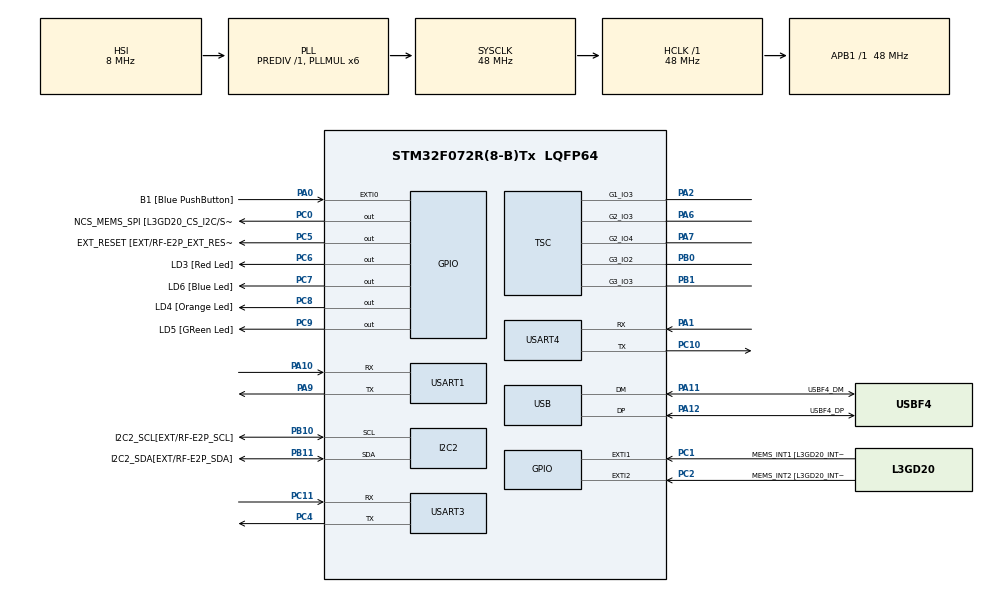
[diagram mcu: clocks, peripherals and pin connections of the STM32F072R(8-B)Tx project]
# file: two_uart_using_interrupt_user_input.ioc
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I2C2.Timing=0x20303E5D
Mcu.Family=STM32F0
Mcu.Name=STM32F072R(8-B)Tx
Mcu.Package=LQFP64
NVIC.USART1_IRQn=true\:0\:0\:false\:false\:true\:true\:true\:true
NVIC.USART3_4_IRQn=true\:0\:0\:false\:false\:true\:true\:true\:true
PA0.GPIO_Label=B1 [Blue PushButton]
PA0.GPIO_ModeDefaultEXTI=GPIO_MODE_EVT_RISING
PA0.Signal=GPXTI0
PA1.Mode=Asynchronous
PA1.Signal=USART4_RX
PA10.Mode=Asynchronous
PA10.Signal=USART1_RX
PA11.GPIO_Label=USBF4_DM
PA11.Mode=Device
PA11.Signal=USB_DM
PA12.GPIO_Label=USBF4_DP
PA12.Mode=Device
PA12.Signal=USB_DP
PA13.GPIO_Label=SWDIO
PA13.Mode=Serial_Wire
PA13.Signal=SYS_SWDIO
PA14.GPIO_Label=SWCLK
PA14.Mode=Serial_Wire
PA14.Signal=SYS_SWCLK
PA2.Mode=G1_IO3-Channel
PA2.Signal=TSC_G1_IO3
PA3.Signal=TSC_G1_IO4
PA6.Mode=G2_IO3-Channel
PA6.Signal=TSC_G2_IO3
PA7.Mode=G2_IO4-Sampling
PA7.Signal=TSC_G2_IO4
PA9.Mode=Asynchronous
PA9.Signal=USART1_TX
PB0.Mode=G3_IO2-Channel
PB0.Signal=TSC_G3_IO2
PB1.Mode=G3_IO3-Sampling
PB1.Signal=TSC_G3_IO3
PB10.GPIO_Label=I2C2_SCL[EXT/RF-E2P_SCL]
PB10.GPIO_Pu=GPIO_PULLUP
PB10.Mode=I2C
PB10.Signal=I2C2_SCL
PB11.GPIO_Label=I2C2_SDA[EXT/RF-E2P_SDA]
PB11.GPIO_Pu=GPIO_PULLUP
PB11.Mode=I2C
PB11.Signal=I2C2_SDA
PB13.Signal=USART3_CTS
PB14.GPIO_Label=SPI2_MISO [L3GD20_SDO]
PB14.Signal=SPI2_MISO
PB15.GPIO_Label=SPI2_MOSI [L3GD20_SDA/SDI]
PB15.Signal=SPI2_MOSI
PC0.GPIO_Label=NCS_MEMS_SPI [L3GD20_CS_I2C/SPI]
PC0.Signal=GPIO_Output
PC1.GPIO_Label=MEMS_INT1 [L3GD20_INT1]
PC1.GPIO_ModeDefaultEXTI=GPIO_MODE_EVT_RISING
PC1.Signal=GPXTI1
PC10.Mode=Asynchronous
PC10.Signal=USART4_TX
PC11.Mode=Asynchronous
PC11.Signal=USART3_RX
PC2.GPIO_Label=MEMS_INT2 [L3GD20_INT2]
PC2.GPIO_ModeDefaultEXTI=GPIO_MODE_EVT_RISING
PC2.Signal=GPXTI2
PC4.Mode=Asynchronous
PC4.Signal=USART3_TX
PC5.GPIO_Label=EXT_RESET [EXT/RF-E2P_EXT_RESET]
PC5.Signal=GPIO_Output
PC6.GPIO_Label=LD3 [Red Led]
PC6.Signal=GPIO_Output
PC7.GPIO_Label=LD6 [Blue Led]
PC7.Signal=GPIO_Output
PC8.GPIO_Label=LD4 [Orange Led]
PC8.Signal=GPIO_Output
PC9.GPIO_Label=LD5 [GReen Led]
PC9.Signal=GPIO_Output
ProjectManager.HeapSize=0x200
ProjectManager.StackSize=0x400
ProjectManager.TargetToolchain=STM32CubeIDE
RCC.AHBFreq_Value=48000000
RCC.APB1Freq_Value=48000000
RCC.APB1TimFreq_Value=48000000
RCC.HCLKFreq_Value=48000000
RCC.PLLMUL=RCC_PLL_MUL6
RCC.SYSCLKFreq_VALUE=48000000
RCC.SYSCLKSource=RCC_SYSCLKSOURCE_PLLCLK
TSC.ChannelIOs-G1_IO3-Channel=TSC_GROUP1_IO3
TSC.ChannelIOs-G2_IO3-Channel=TSC_GROUP2_IO3
TSC.ChannelIOs-G3_IO2-Channel=TSC_GROUP3_IO2
TSC.SamplingIOs-G2_IO4-Sampling=TSC_GROUP2_IO4
TSC.SamplingIOs-G3_IO3-Sampling=TSC_GROUP3_IO3
USART1.VirtualMode-Asynchronous=VM_ASYNC
USART3.VirtualMode-Asynchronous=VM_ASYNC
USART4.VirtualMode-Asynchronous=VM_ASYNC
USB.phy_itface=PCD_PHY_EMBEDDED
USB.speed=PCD_SPEED_FULL
board=STM32F072B-DISCO

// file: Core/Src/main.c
/* USER CODE BEGIN Header */
/**
  ******************************************************************************
  * @file           : main.c
  * @brief          : Main program body
  ******************************************************************************
  * @attention
  *
  * Copyright (c) 2026 STMicroelectronics.
  * All rights reserved.
  *
  * This software is licensed under terms that can be found in the LICENSE file
  * in the root directory of this software component.
  * If no LICENSE file comes with this software, it is provided AS-IS.
  *
  ******************************************************************************
  */
/* USER CODE END Header */
#include "main.h"

I2C_HandleTypeDef hi2c2;

TSC_HandleTypeDef htsc;

UART_HandleTypeDef huart1;
UART_HandleTypeDef huart3;
UART_HandleTypeDef huart4;

PCD_HandleTypeDef hpcd_USB_FS;

/* USER CODE BEGIN PV */
uint8_t usart3_rx;
uint8_t usart4_rx;

volatile uint8_t usart3_flag = 0;
volatile uint8_t usart4_flag = 0;
/* USER CODE END PV */

void SystemClock_Config(void);
static void MX_GPIO_Init(void);
static void MX_I2C2_Init(void);
static void MX_TSC_Init(void);
static void MX_USB_PCD_Init(void);
static void MX_USART1_UART_Init(void);
static void MX_USART4_UART_Init(void);
static void MX_USART3_UART_Init(void);

int main(void)
{

  /* MCU Configuration--------------------------------------------------------*/

  /* Reset of all peripherals, Initializes the Flash interface and the Systick. */
  HAL_Init();

  /* Configure the system clock */
  SystemClock_Config();

  /* Initialize all configured peripherals */
  MX_GPIO_Init();
  MX_I2C2_Init();
  MX_TSC_Init();
  MX_USB_PCD_Init();
  MX_USART1_UART_Init();
  MX_USART4_UART_Init();
  MX_USART3_UART_Init();
  /* USER CODE BEGIN 2 */
  HAL_UART_Receive_IT(&huart3, &usart3_rx, 1);
  HAL_UART_Receive_IT(&huart4, &usart4_rx, 1);
  /* USER CODE END 2 */

  /* Infinite loop */
  /* USER CODE BEGIN WHILE */
  while (1)
  {
      if (usart3_flag)
      {
          usart3_flag = 0;

          HAL_UART_Transmit(&huart4,
                            &usart3_rx,
                            1,
                            HAL_MAX_DELAY);
      }

      if (usart4_flag)
      {
          usart4_flag = 0;

          HAL_UART_Transmit(&huart3,
                            &usart4_rx,
                            1,
                            HAL_MAX_DELAY);
      }
  }
}

void SystemClock_Config(void)
{
  RCC_OscInitTypeDef RCC_OscInitStruct = {0};
  RCC_ClkInitTypeDef RCC_ClkInitStruct = {0};
  RCC_PeriphCLKInitTypeDef PeriphClkInit = {0};

  /** Initializes the RCC Oscillators according to the specified parameters
  * in the RCC_OscInitTypeDef structure.
  */
  RCC_OscInitStruct.OscillatorType = RCC_OSCILLATORTYPE_HSI|RCC_OSCILLATORTYPE_HSI48;
  RCC_OscInitStruct.HSIState = RCC_HSI_ON;
  RCC_OscInitStruct.HSI48State = RCC_HSI48_ON;
  RCC_OscInitStruct.HSICalibrationValue = RCC_HSICALIBRATION_DEFAULT;
  RCC_OscInitStruct.PLL.PLLState = RCC_PLL_ON;
  RCC_OscInitStruct.PLL.PLLSource = RCC_PLLSOURCE_HSI;
  RCC_OscInitStruct.PLL.PLLMUL = RCC_PLL_MUL6;
  RCC_OscInitStruct.PLL.PREDIV = RCC_PREDIV_DIV1;
  if (HAL_RCC_OscConfig(&RCC_OscInitStruct) != HAL_OK)
  {
    Error_Handler();
  }

  /** Initializes the CPU, AHB and APB buses clocks
  */
  RCC_ClkInitStruct.ClockType = RCC_CLOCKTYPE_HCLK|RCC_CLOCKTYPE_SYSCLK
                              |RCC_CLOCKTYPE_PCLK1;
  RCC_ClkInitStruct.SYSCLKSource = RCC_SYSCLKSOURCE_PLLCLK;
  RCC_ClkInitStruct.AHBCLKDivider = RCC_SYSCLK_DIV1;
  RCC_ClkInitStruct.APB1CLKDivider = RCC_HCLK_DIV1;

  if (HAL_RCC_ClockConfig(&RCC_ClkInitStruct, FLASH_LATENCY_1) != HAL_OK)
  {
    Error_Handler();
  }
  PeriphClkInit.PeriphClockSelection = RCC_PERIPHCLK_USB|RCC_PERIPHCLK_USART1;
  PeriphClkInit.Usart1ClockSelection = RCC_USART1CLKSOURCE_PCLK1;
  PeriphClkInit.UsbClockSelection = RCC_USBCLKSOURCE_HSI48;

  if (HAL_RCCEx_PeriphCLKConfig(&PeriphClkInit) != HAL_OK)
  {
    Error_Handler();
  }
}

static void MX_I2C2_Init(void)
{

  hi2c2.Instance = I2C2;
  hi2c2.Init.Timing = 0x20303E5D;
  hi2c2.Init.OwnAddress1 = 0;
  hi2c2.Init.AddressingMode = I2C_ADDRESSINGMODE_7BIT;
  hi2c2.Init.DualAddressMode = I2C_DUALADDRESS_DISABLE;
  hi2c2.Init.OwnAddress2 = 0;
  hi2c2.Init.OwnAddress2Masks = I2C_OA2_NOMASK;
  hi2c2.Init.GeneralCallMode = I2C_GENERALCALL_DISABLE;
  hi2c2.Init.NoStretchMode = I2C_NOSTRETCH_DISABLE;
  if (HAL_I2C_Init(&hi2c2) != HAL_OK)
  {
    Error_Handler();
  }

  /** Configure Analogue filter
  */
  if (HAL_I2CEx_ConfigAnalogFilter(&hi2c2, I2C_ANALOGFILTER_ENABLE) != HAL_OK)
  {
    Error_Handler();
  }

  /** Configure Digital filter
  */
  if (HAL_I2CEx_ConfigDigitalFilter(&hi2c2, 0) != HAL_OK)
  {
    Error_Handler();
  }

}

static void MX_TSC_Init(void)
{

  /** Configure the TSC peripheral
  */
  htsc.Instance = TSC;
  htsc.Init.CTPulseHighLength = TSC_CTPH_2CYCLES;
  htsc.Init.CTPulseLowLength = TSC_CTPL_2CYCLES;
  htsc.Init.SpreadSpectrum = DISABLE;
  htsc.Init.SpreadSpectrumDeviation = 1;
  htsc.Init.SpreadSpectrumPrescaler = TSC_SS_PRESC_DIV1;
  htsc.Init.PulseGeneratorPrescaler = TSC_PG_PRESC_DIV4;
  htsc.Init.MaxCountValue = TSC_MCV_8191;
  htsc.Init.IODefaultMode = TSC_IODEF_OUT_PP_LOW;
  htsc.Init.SynchroPinPolarity = TSC_SYNC_POLARITY_FALLING;
  htsc.Init.AcquisitionMode = TSC_ACQ_MODE_NORMAL;
  htsc.Init.MaxCountInterrupt = DISABLE;
  htsc.Init.ChannelIOs = TSC_GROUP1_IO3|TSC_GROUP2_IO3|TSC_GROUP3_IO2;
  htsc.Init.ShieldIOs = 0;
  htsc.Init.SamplingIOs = TSC_GROUP2_IO4|TSC_GROUP3_IO3;
  if (HAL_TSC_Init(&htsc) != HAL_OK)
  {
    Error_Handler();
  }

}

static void MX_USART1_UART_Init(void)
{

  huart1.Instance = USART1;
  huart1.Init.BaudRate = 38400;
  huart1.Init.WordLength = UART_WORDLENGTH_8B;
  huart1.Init.StopBits = UART_STOPBITS_1;
  huart1.Init.Parity = UART_PARITY_NONE;
  huart1.Init.Mode = UART_MODE_TX_RX;
  huart1.Init.HwFlowCtl = UART_HWCONTROL_NONE;
  huart1.Init.OverSampling = UART_OVERSAMPLING_16;
  huart1.Init.OneBitSampling = UART_ONE_BIT_SAMPLE_DISABLE;
  huart1.AdvancedInit.AdvFeatureInit = UART_ADVFEATURE_NO_INIT;
  if (HAL_UART_Init(&huart1) != HAL_OK)
  {
    Error_Handler();
  }

}

static void MX_USART3_UART_Init(void)
{

  huart3.Instance = USART3;
  huart3.Init.BaudRate = 38400;
  huart3.Init.WordLength = UART_WORDLENGTH_8B;
  huart3.Init.StopBits = UART_STOPBITS_1;
  huart3.Init.Parity = UART_PARITY_NONE;
  huart3.Init.Mode = UART_MODE_TX_RX;
  huart3.Init.HwFlowCtl = UART_HWCONTROL_NONE;
  huart3.Init.OverSampling = UART_OVERSAMPLING_16;
  huart3.Init.OneBitSampling = UART_ONE_BIT_SAMPLE_DISABLE;
  huart3.AdvancedInit.AdvFeatureInit = UART_ADVFEATURE_NO_INIT;
  if (HAL_UART_Init(&huart3) != HAL_OK)
  {
    Error_Handler();
  }

}

static void MX_USART4_UART_Init(void)
{

  huart4.Instance = USART4;
  huart4.Init.BaudRate = 38400;
  huart4.Init.WordLength = UART_WORDLENGTH_8B;
  huart4.Init.StopBits = UART_STOPBITS_1;
  huart4.Init.Parity = UART_PARITY_NONE;
  huart4.Init.Mode = UART_MODE_TX_RX;
  huart4.Init.HwFlowCtl = UART_HWCONTROL_NONE;
  huart4.Init.OverSampling = UART_OVERSAMPLING_16;
  huart4.Init.OneBitSampling = UART_ONE_BIT_SAMPLE_DISABLE;
  huart4.AdvancedInit.AdvFeatureInit = UART_ADVFEATURE_NO_INIT;
  if (HAL_UART_Init(&huart4) != HAL_OK)
  {
    Error_Handler();
  }

}

static void MX_USB_PCD_Init(void)
{

  hpcd_USB_FS.Instance = USB;
  hpcd_USB_FS.Init.dev_endpoints = 8;
  hpcd_USB_FS.Init.speed = PCD_SPEED_FULL;
  hpcd_USB_FS.Init.phy_itface = PCD_PHY_EMBEDDED;
  hpcd_USB_FS.Init.low_power_enable = DISABLE;
  hpcd_USB_FS.Init.lpm_enable = DISABLE;
  hpcd_USB_FS.Init.battery_charging_enable = DISABLE;
  if (HAL_PCD_Init(&hpcd_USB_FS) != HAL_OK)
  {
    Error_Handler();
  }

}

static void MX_GPIO_Init(void)
{
  GPIO_InitTypeDef GPIO_InitStruct = {0};

  /* GPIO Ports Clock Enable */
  __HAL_RCC_GPIOC_CLK_ENABLE();
  __HAL_RCC_GPIOA_CLK_ENABLE();
  __HAL_RCC_GPIOB_CLK_ENABLE();

  /*Configure GPIO pin Output Level */
  HAL_GPIO_WritePin(GPIOC, NCS_MEMS_SPI_Pin|EXT_RESET_Pin|LD3_Pin|LD6_Pin
                          |LD4_Pin|LD5_Pin, GPIO_PIN_RESET);

  /*Configure GPIO pins : NCS_MEMS_SPI_Pin EXT_RESET_Pin LD3_Pin LD6_Pin
                           LD4_Pin LD5_Pin */
  GPIO_InitStruct.Pin = NCS_MEMS_SPI_Pin|EXT_RESET_Pin|LD3_Pin|LD6_Pin
                          |LD4_Pin|LD5_Pin;
  GPIO_InitStruct.Mode = GPIO_MODE_OUTPUT_PP;
  GPIO_InitStruct.Pull = GPIO_NOPULL;
  GPIO_InitStruct.Speed = GPIO_SPEED_FREQ_LOW;
  HAL_GPIO_Init(GPIOC, &GPIO_InitStruct);

  /*Configure GPIO pins : MEMS_INT1_Pin MEMS_INT2_Pin */
  GPIO_InitStruct.Pin = MEMS_INT1_Pin|MEMS_INT2_Pin;
  GPIO_InitStruct.Mode = GPIO_MODE_EVT_RISING;
  GPIO_InitStruct.Pull = GPIO_NOPULL;
  HAL_GPIO_Init(GPIOC, &GPIO_InitStruct);

  /*Configure GPIO pin : B1_Pin */
  GPIO_InitStruct.Pin = B1_Pin;
  GPIO_InitStruct.Mode = GPIO_MODE_EVT_RISING;
  GPIO_InitStruct.Pull = GPIO_NOPULL;
  HAL_GPIO_Init(B1_GPIO_Port, &GPIO_InitStruct);

  /*Configure GPIO pins : SPI2_MISO_Pin SPI2_MOSI_Pin */
  GPIO_InitStruct.Pin = SPI2_MISO_Pin|SPI2_MOSI_Pin;
  GPIO_InitStruct.Mode = GPIO_MODE_AF_PP;
  GPIO_InitStruct.Pull = GPIO_NOPULL;
  GPIO_InitStruct.Speed = GPIO_SPEED_FREQ_HIGH;
  GPIO_InitStruct.Alternate = GPIO_AF0_SPI2;
  HAL_GPIO_Init(GPIOB, &GPIO_InitStruct);

}

/* USER CODE BEGIN 4 */
void HAL_UART_RxCpltCallback(UART_HandleTypeDef *huart)
{
    if (huart->Instance == USART3)
    {
        usart3_flag = 1;
        HAL_UART_Receive_IT(&huart3, &usart3_rx, 1);
    }
    else if (huart->Instance == USART4)
    {
        usart4_flag = 1;
        HAL_UART_Receive_IT(&huart4, &usart4_rx, 1);
    }
}
/* USER CODE END 4 */

void Error_Handler(void)
{
  __disable_irq();
  while (1)
  {
  }
}
